VERSION ""

BU_: AMS VCU ECU

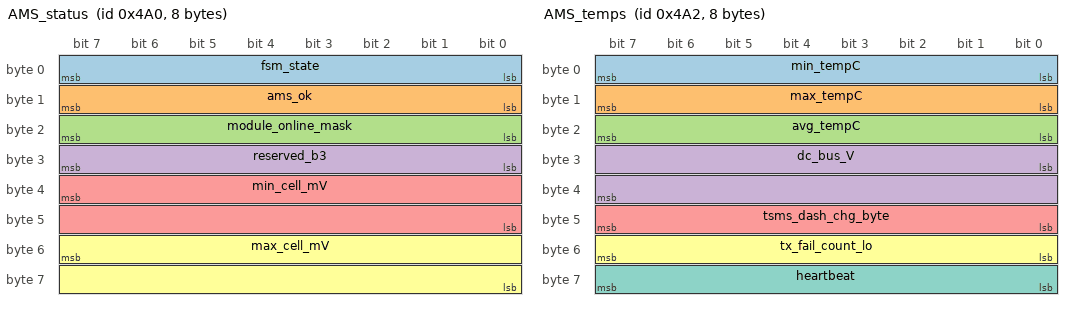
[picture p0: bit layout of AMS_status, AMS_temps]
BO_ 1184 AMS_status: 8 AMS
 SG_ fsm_state : 0|8@1+ (1,0) [0|0] "enum" Vector__XXX
 SG_ ams_ok : 8|8@1+ (1,0) [0|0] "bool" Vector__XXX
 SG_ module_online_mask : 16|8@1+ (1,0) [0|0] "bitmask" Vector__XXX
 SG_ reserved_b3 : 24|8@1+ (1,0) [0|0] "" Vector__XXX
 SG_ min_cell_mV : 39|16@0+ (1,0) [0|0] "mV" Vector__XXX
 SG_ max_cell_mV : 55|16@0+ (1,0) [0|0] "mV" Vector__XXX

BO_ 1185 AMS_pack: 8 AMS
 SG_ pack_voltage_mV : 0|32@1+ (1,0) [0|0] "mV" Vector__XXX
 SG_ filtered_mA : 32|32@1- (1,0) [0|0] "mA" Vector__XXX

BO_ 1186 AMS_temps: 8 AMS
 SG_ min_tempC : 0|8@1- (1,0) [0|0] "degC" Vector__XXX
 SG_ max_tempC : 8|8@1- (1,0) [0|0] "degC" Vector__XXX
 SG_ avg_tempC : 16|8@1- (1,0) [0|0] "degC" Vector__XXX
 SG_ dc_bus_V : 24|16@1+ (1,0) [0|0] "V" Vector__XXX
 SG_ tsms_dash_chg_byte : 40|8@1+ (1,0) [0|0] "bitfield" Vector__XXX
 SG_ tx_fail_count_lo : 48|8@1+ (1,0) [0|0] "" Vector__XXX
 SG_ heartbeat : 56|8@1+ (1,0) [0|0] "" Vector__XXX
